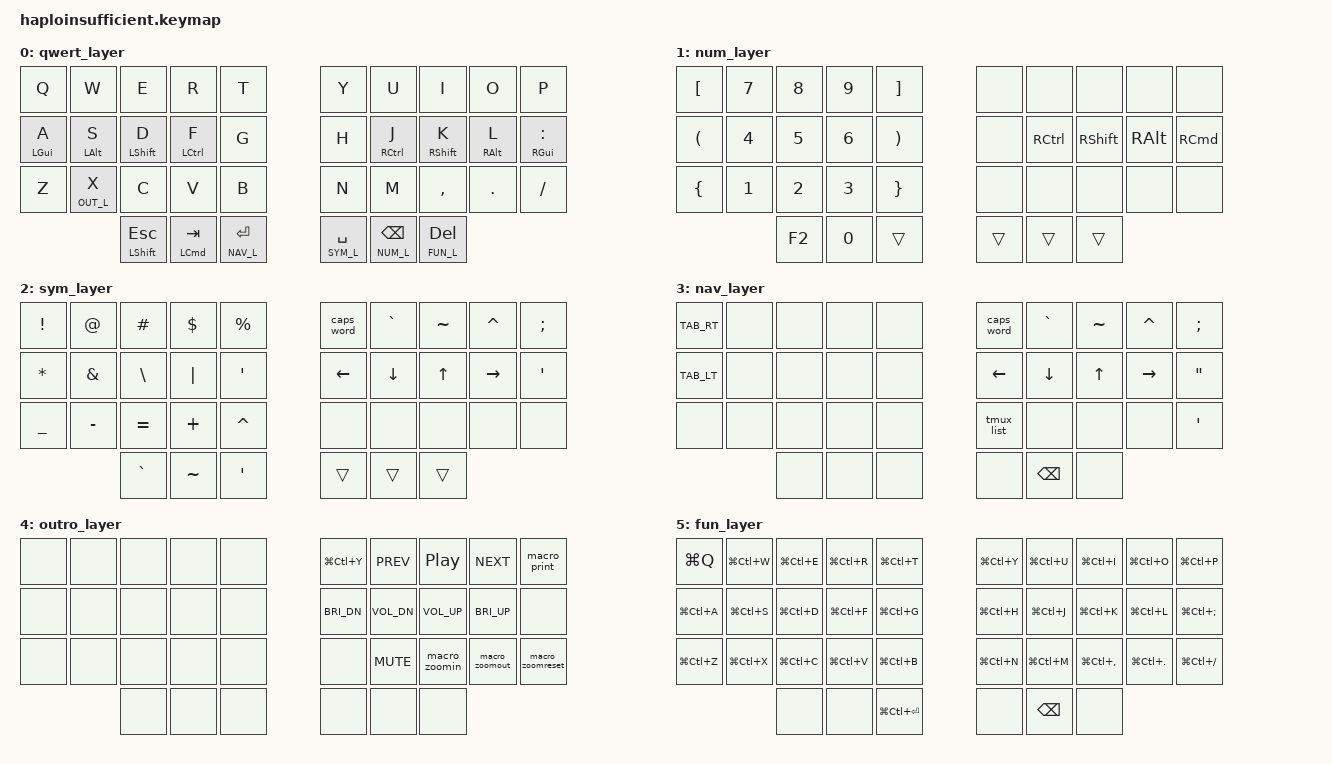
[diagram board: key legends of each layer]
/*
 * Copyright (c) 2021 The ZMK Contributors
 *
 * SPDX-License-Identifier: MIT
 */

#include <behaviors.dtsi>
#include <dt-bindings/zmk/bt.h>
#include <dt-bindings/zmk/keys.h>

//&sk {
//    release-after-ms = <750>;
//    quick-release;
//};

&mt {
    tapping-term-ms = <200>;
    quick_tap_ms = <0>;
    flavor = "tap-preferred";
};

&lt {
    tapping-term-ms = <200>;
    quick_tap_ms = <0>;
    flavor = "tap-preferred";
};

&caps_word {
    continue-list = <DEL MINUS BSPC>;
};

#define QWERT_L 0
#define NUM_L   1
#define SYM_L   2
#define NAV_L   3
#define OUT_L   4
#define FUN_L   5

#define MY_COPY LC(INSERT)
#define MY_PASTE LS(INSERT)
//#define VI_U LC(Z)
//#define VI_W LC(RIGHT)
//#define VI_B LC(LEFT)

#define CCA &kp LG(LC(A))
#define CCB &kp LG(LC(B))
#define CCC &kp LG(LC(C))
#define CCD &kp LG(LC(D))
#define CCE &kp LG(LC(E))
#define CCF &kp LG(LC(F))
#define CCG &kp LG(LC(G))
#define CCH &kp LG(LC(H))
#define CCI &kp LG(LC(I))
#define CCJ &kp LG(LC(J))
#define CCK &kp LG(LC(K))
#define CCL &kp LG(LC(L))
#define CCM &kp LG(LC(M))
#define CCN &kp LG(LC(N))
#define CCO &kp LG(LC(O))
#define CCP &kp LG(LC(P))
#define CCQ &kp LG(LC(Q))
#define CCR &kp LG(LC(R))
#define CCS &kp LG(LC(S))
#define CCT &kp LG(LC(T))
#define CCU &kp LG(LC(U))
#define CCV &kp LG(LC(V))
#define CCW &kp LG(LC(W))
#define CCX &kp LG(LC(X))
#define CCY &kp LG(LC(Y))
#define CCZ &kp LG(LC(Z))
#define CC_C &kp LG(LC(COMMA))
#define CC_D &kp LG(LC(DOT))
#define CC_L &kp LG(LC(SEMI))
#define CC_S &kp LG(LC(SLASH))

#define TAB_RT LC(TAB)
#define TAB_LT LC(LS(TAB))

/ {
    combos {
        compatible = "zmk,combos";

    // shortcut
    #define COMBO(NAME, BINDINGS, KEYPOS, TIMEOUT) \
          combo_##NAME { \
            timeout-ms = <TIMEOUT>; \
            bindings = <BINDINGS>; \
            key-positions = <KEYPOS>; \
          };

        /*                KEY POSITIONS

          ╭────────────────────╮ ╭────────────────────╮
          │  0   1   2   3   4 │ │  5   6   7   8   9 │
          │ 10  11  12  13  14 │ │ 15  16  17  18  19 │
          │ 20  21  22  23  24 │ │ 25  26  27  28  29 │
          ╰───────╮ 30  31  32 │ │ 33  34  35 ╭───────╯
                  ╰────────────╯ ╰────────────╯        */


        //COMBO(semicolon, &kp SEMI, 18 19, 60
        //COMBO(slash, &kp FSLH, 1 2, 60)
        //COMBO(escape, &kp ESC, 0 1, 60)
        COMBO(minus, &kp MINUS, 31 34, 60)
        COMBO(underscore, &kp UNDER, 32 33, 60)
        COMBO(equal, &kp EQUAL, 30 35, 60)
        COMBO(plus, &kp PLUS, 20 29, 60)
        // COMBO(reset_left, &bootloader, 0 1 2 3, 100)
        //COMBO(reset_right, &bootloader, 6 7 8 9, 100)
    };

    macros {
        tmux_list: tmux_list {
            label = "tmux_list";
            compatible = "zmk,behavior-macro";
            #binding-cells = <0>;
            bindings
                = <&macro_press &kp LCTRL>
                , <&macro_tap &kp A>
                , <&macro_release &kp LCTRL>
                , <&macro_tap &kp N0>
                ;
        };
        macro_u: macro_u {
            label = "macro_u";
            compatible = "zmk,behavior-macro";
            #binding-cells = <0>;
            bindings
                = <&macro_press &kp LCTRL>
                , <&macro_press &kp LCMD>
                , <&macro_press &kp U>
                , <&macro_release &kp LCTRL>
                , <&macro_release &kp LCMD>
                , <&macro_release &kp U>
                ;
        };
        macro_i: macro_i {
            label = "macro_i";
            compatible = "zmk,behavior-macro";
            #binding-cells = <0>;
            bindings
                = <&macro_press &kp LCTRL>
                , <&macro_press &kp LCMD>
                , <&macro_press &kp I>
                , <&macro_release &kp LCTRL>
                , <&macro_release &kp LCMD>
                , <&macro_release &kp I>
                ;
        };
        macro_n: macro_n {
            label = "macro_n";
            compatible = "zmk,behavior-macro";
            #binding-cells = <0>;
            bindings
                = <&macro_press &kp LCTRL>
                , <&macro_press &kp LCMD>
                , <&macro_press &kp N>
                , <&macro_release &kp LCTRL>
                , <&macro_release &kp LCMD>
                , <&macro_release &kp N>
                ;
        };
        macro_m: macro_m {
            label = "macro_m";
            compatible = "zmk,behavior-macro";
            #binding-cells = <0>;
            bindings
                = <&macro_press &kp LCTRL>
                , <&macro_press &kp LCMD>
                , <&macro_press &kp M>
                , <&macro_release &kp LCTRL>
                , <&macro_release &kp LCMD>
                , <&macro_release &kp M>
                ;
        };
        macro_d: macro_d {
            label = "macro_d";
            compatible = "zmk,behavior-macro";
            #binding-cells = <0>;
            bindings
                = <&macro_press &kp LCTRL>
                , <&macro_press &kp LCMD>
                , <&macro_press &kp D>
                , <&macro_release &kp LCTRL>
                , <&macro_release &kp LCMD>
                , <&macro_release &kp D>
                ;
        };
        macro_comma: macro_comma {
            label = "macro_comma";
            compatible = "zmk,behavior-macro";
            #binding-cells = <0>;
            bindings
                = <&macro_press &kp LCTRL>
                , <&macro_press &kp LCMD>
                , <&macro_press &kp COMMA>
                , <&macro_release &kp LCTRL>
                , <&macro_release &kp LCMD>
                , <&macro_release &kp COMMA>
                ;
        };
        macro_print: macro_print {
            label = "macro_print";
            compatible = "zmk,behavior-macro";
            #binding-cells = <0>;
            bindings
                = <&macro_press &kp LCMD>
                , <&macro_press &kp LSHFT>
                , <&macro_press &kp N2>
                , <&macro_release &kp LCMD>
                , <&macro_release &kp LSHFT>
                , <&macro_release &kp N2>
                ;
        };

        macro_zoomin: macro_zoomin {
            label = "macro_zoomin";
            compatible = "zmk,behavior-macro";
            #binding-cells = <0>;
            bindings
                = <&macro_press &kp LCMD>
                , <&macro_press &kp PLUS>
                , <&macro_release &kp LCMD>
                , <&macro_release &kp PLUS>
                ;
        };

        macro_zoomout: macro_zoomout {
            label = "macro_zoomout";
            compatible = "zmk,behavior-macro";
            #binding-cells = <0>;
            bindings
                = <&macro_press &kp LCMD>
                , <&macro_press &kp MINUS>
                , <&macro_release &kp LCMD>
                , <&macro_release &kp MINUS>
                ;
        };

        macro_zoomreset: macro_zoomreset {
            label = "macro_zoomreset";
            compatible = "zmk,behavior-macro";
            #binding-cells = <0>;
            bindings
                = <&macro_press &kp LCMD>
                , <&macro_press &kp N0>
                , <&macro_release &kp LCMD>
                , <&macro_release &kp N0>
                ;
        };

    };

    behaviors {
        bhm: balanced_homerow_mods {
            compatible = "zmk,behavior-hold-tap";
            label = "HOMEROW_MODS";
            #binding-cells = <2>;
            tapping-term-ms = <200>;    // <---[[moderate duration]]
            quick-tap-ms = <185>;
            flavor = "balanced";
            bindings = <&kp>, <&kp>;
        };
    };

	keymap {
		compatible = "zmk,keymap";

        // QWERTY
		qwert_layer {
			bindings = <
                   &kp     Q    &kp W         &kp E         &kp R              &kp T              &kp Y               &kp U            &kp I                 &kp O         &kp P
                   &bhm LGUI A &bhm LALT  S   &bhm LSHFT D  &bhm LCTRL F       &kp G              &kp H               &bhm RCTRL J      &bhm RSHFT K           &bhm RALT L    &bhm RGUI COLON
                   &kp Z  &lt OUT_L X  &kp C         &kp V              &kp B              &kp N               &kp M            &kp COMMA             &kp DOT       &kp SLASH
				 /*&            &*/              &bhm LSHFT ESC   &bhm LCMD TAB  &lt NAV_L RET     &lt SYM_L SPACE  &lt NUM_L BSPC       &lt FUN_L DEL     /*  &             &*/
			>;
		};

		num_layer {
			bindings = <
                   &kp LBKT     &kp N7        &kp N8        &kp N9             &kp RBKT           &none               &none            &none                 &none         &none
                   &kp LPAR     &kp N4        &kp N5        &kp N6             &kp RPAR           &none               &kp RCTRL        &kp RSHFT             &kp RALT      &kp RCMD
                   &kp LBRC     &kp N1        &kp N2        &kp N3             &kp RBRC           &none               &none            &none                 &none         &none
				 /*&            &*/         &kp F2             &kp N0             &trans              &trans           &trans                &trans     /*             &             &*/
			>;
		};

		sym_layer {
			bindings = <
                   &kp EXCL     &kp AT        &kp HASH      &kp DLLR           &kp PRCNT          &caps_word          &kp GRAVE       &kp TILDE             &kp CARET     &kp SEMI
                   &kp STAR     &kp AMPS      &kp BSLH      &kp PIPE           &kp SQT            &kp LEFT            &kp DOWN        &kp UP                &kp RIGHT     &kp SQT
                   &kp UNDER    &kp MINUS     &kp EQUAL     &kp PLUS           &kp CARET          &none               &none           &none                 &none         &none
				 /*&            &*/         &kp GRAVE          &kp TILDE          &kp SQT              &trans           &trans                   &trans     /*             &             &*/
			>;
		};

		nav_layer {
			bindings = <
                   TAB_RT        &none         &none         &none              &none             &caps_word          &kp GRAVE           &kp TILDE               &kp CARET     &kp SEMI
                   TAB_LT        &none         &none         &none              &none             &kp LEFT            &kp DOWN         &kp UP                   &kp RIGHT     &kp DQT
                   &none        &none         &none         &none              &none             &tmux_list          &none            &none                    &none         &kp SQT
				 /*&            &*/         &none              &none             &none               &none            &kp BSPC                 &none     /*            &             &*/
			>;
		};

		outro_layer {
			bindings = <
                   &none        &none         &none         &none              &none             CCY                 &kp C_PREV       &kp C_PP                 &kp C_NEXT    &macro_print
                   &none        &none         &none         &none              &none             &kp C_BRI_DN        &kp C_VOL_DN     &kp C_VOL_UP             &kp C_BRI_UP  &none
                   &none        &none         &none         &none              &none             &none               &kp C_MUTE       &macro_zoomin            &macro_zoomout &macro_zoomreset
				 /*&            &*/         &none              &none             &none               &none            &none                    &none     /*            &             &*/
			>;
		};

		fun_layer {
			bindings = <
                   &kp LG(Q)       CCW             CCE             CCR            CCT        CCY          CCU          CCI           CCO           CCP
                   CCA             CCS             CCD             CCF            CCG        CCH          CCJ          CCK           CCL           CC_L
                   CCZ             CCX             CCC             CCV            CCB        CCN          CCM          CC_C          CC_D          CC_S
		   /*&             &*/             &none           &none          &kp LG(LC(RET))   &none        &kp BSPC     &none         /*&           &*/
			>;
		};
	};
};
